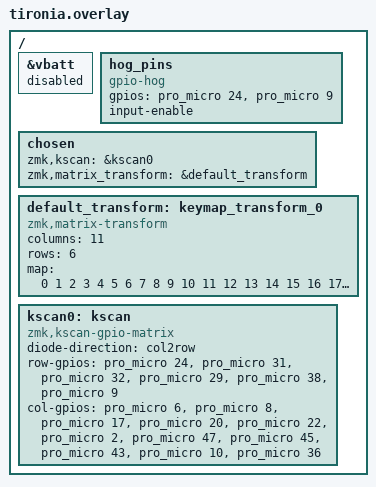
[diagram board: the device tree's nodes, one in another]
#include <dt-bindings/zmk/matrix_transform.h>

/ {

    &vbatt {
        status = "disabled";
    };

    hog_pins: hog_pins {
        compatible = "gpio-hog";
        gpios
            = <&pro_micro 24 GPIO_ACTIVE_HIGH>
            , <&pro_micro 9 GPIO_ACTIVE_HIGH>
            ;
        input-enable;
    };

    chosen {
        zmk,kscan = &kscan0;
        zmk,matrix_transform = &default_transform;
    };

    default_transform: keymap_transform_0 {
        compatible = "zmk,matrix-transform";
        columns = <11>;
        rows = <6>;

        map = <
            0  1  2  3  4
            5  6  7  8  9 10
            11 12 13 14 15
            16 17 18 19 20 21
            22 23 24
            25 26 27
        >;
    };

    kscan0: kscan {
        compatible = "zmk,kscan-gpio-matrix";
        diode-direction = "col2row";
        
        row-gpios
            = <&pro_micro 24 (GPIO_ACTIVE_HIGH | GPIO_PULL_DOWN)>
            , <&pro_micro 31 (GPIO_ACTIVE_HIGH | GPIO_PULL_DOWN)>
            , <&pro_micro 32 (GPIO_ACTIVE_HIGH | GPIO_PULL_DOWN)>
            , <&pro_micro 29 (GPIO_ACTIVE_HIGH | GPIO_PULL_DOWN)>
            , <&pro_micro 38 (GPIO_ACTIVE_HIGH | GPIO_PULL_DOWN)>
            , <&pro_micro 9 (GPIO_ACTIVE_HIGH | GPIO_PULL_DOWN)>
            ;
        
        col-gpios
            = <&pro_micro 6 (GPIO_ACTIVE_HIGH)>
            , <&pro_micro 8 (GPIO_ACTIVE_HIGH)>
            , <&pro_micro 17 (GPIO_ACTIVE_HIGH)>
            , <&pro_micro 20 (GPIO_ACTIVE_HIGH)>
            , <&pro_micro 22 (GPIO_ACTIVE_HIGH)>
            , <&pro_micro 2 (GPIO_ACTIVE_HIGH)>
            , <&pro_micro 47 (GPIO_ACTIVE_HIGH)>
            , <&pro_micro 45 (GPIO_ACTIVE_HIGH)>
            , <&pro_micro 43 (GPIO_ACTIVE_HIGH)>
            , <&pro_micro 10 (GPIO_ACTIVE_HIGH)>
            , <&pro_micro 36 (GPIO_ACTIVE_HIGH)>
            ;
    };
};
